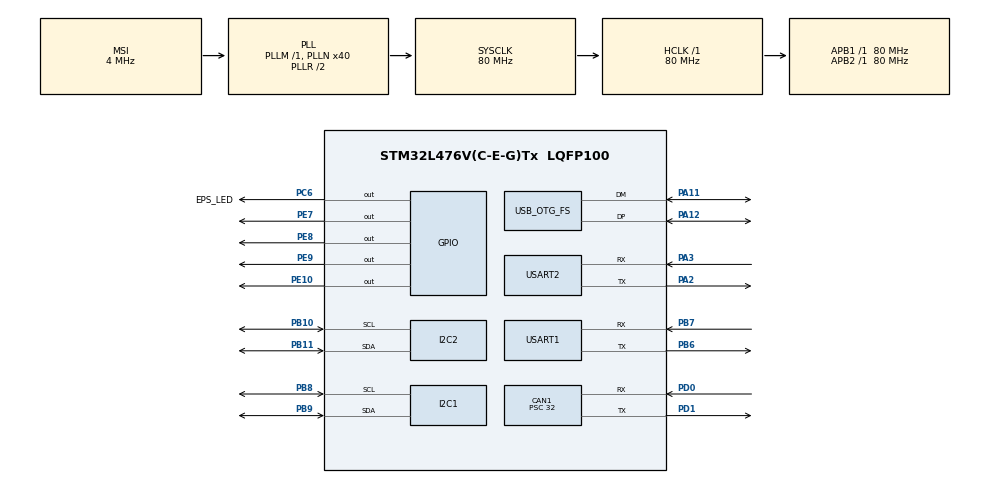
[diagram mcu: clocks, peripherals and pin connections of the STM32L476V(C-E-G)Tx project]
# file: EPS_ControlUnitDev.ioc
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CAN1.CalculateBaudRate=833333
CAN1.CalculateTimeBit=1200
CAN1.CalculateTimeQuantum=400.0
CAN1.Prescaler=32
I2C1.Timing=0x10D19CE4
I2C2.Timing=0x10D19CE4
Mcu.Family=STM32L4
Mcu.Name=STM32L476V(C-E-G)Tx
Mcu.Package=LQFP100
NVIC.OTG_FS_IRQn=true\:0\:0\:false\:false\:true\:false\:true\:true
NVIC.PriorityGroup=NVIC_PRIORITYGROUP_4
PA11.Mode=Device_Only
PA11.Signal=USB_OTG_FS_DM
PA12.Mode=Device_Only
PA12.Signal=USB_OTG_FS_DP
PA13\ (JTMS-SWDIO).Mode=Serial_Wire
PA13\ (JTMS-SWDIO).Signal=SYS_JTMS-SWDIO
PA14\ (JTCK-SWCLK).Mode=Serial_Wire
PA14\ (JTCK-SWCLK).Signal=SYS_JTCK-SWCLK
PA2.Mode=Asynchronous
PA2.Signal=USART2_TX
PA3.Mode=Asynchronous
PA3.Signal=USART2_RX
PB10.Mode=I2C
PB10.Signal=I2C2_SCL
PB11.Mode=I2C
PB11.Signal=I2C2_SDA
PB6.Mode=Asynchronous
PB6.Signal=USART1_TX
PB7.Mode=Asynchronous
PB7.Signal=USART1_RX
PB8.Mode=I2C
PB8.Signal=I2C1_SCL
PB9.Mode=I2C
PB9.Signal=I2C1_SDA
PC6.GPIO_Label=EPS_LED
PC6.Signal=GPIO_Output
PD0.Mode=CAN_Activate
PD0.Signal=CAN1_RX
PD1.Mode=CAN_Activate
PD1.Signal=CAN1_TX
PE10.Signal=GPIO_Output
PE7.Signal=GPIO_Output
PE8.Signal=GPIO_Output
PE9.Signal=GPIO_Output
PH0-OSC_IN\ (PH0).Mode=HSE-External-Oscillator
PH0-OSC_IN\ (PH0).Signal=RCC_OSC_IN
PH1-OSC_OUT\ (PH1).Mode=HSE-External-Oscillator
PH1-OSC_OUT\ (PH1).Signal=RCC_OSC_OUT
ProjectManager.HeapSize=0x200
ProjectManager.StackSize=0x400
ProjectManager.TargetToolchain=STM32CubeIDE
RCC.ADCFreq_Value=48000000
RCC.AHBFreq_Value=80000000
RCC.APB1Freq_Value=80000000
RCC.APB1TimFreq_Value=80000000
RCC.APB2Freq_Value=80000000
RCC.APB2TimFreq_Value=80000000
RCC.CortexFreq_Value=80000000
RCC.HCLKFreq_Value=80000000
RCC.HSE_VALUE=32000000
RCC.HSI_VALUE=16000000
RCC.LSE_VALUE=32768
RCC.MSI_VALUE=4000000
RCC.PLLN=40
RCC.PLLSAI1N=24
RCC.SYSCLKFreq_VALUE=80000000
RCC.SYSCLKSource=RCC_SYSCLKSOURCE_PLLCLK
RCC.USBFreq_Value=48000000
RCC.VCOOutputFreq_Value=160000000
USART1.VirtualMode-Asynchronous=VM_ASYNC
USART2.VirtualMode-Asynchronous=VM_ASYNC
USB_DEVICE.CLASS_NAME_FS=CDC
USB_DEVICE.VirtualMode=Cdc
USB_DEVICE.VirtualModeFS=Cdc_FS
USB_OTG_FS.VirtualMode=Device_Only
VP_USB_DEVICE_VS_USB_DEVICE_CDC_FS.Mode=CDC_FS
board=custom

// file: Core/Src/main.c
/* USER CODE BEGIN Header */
/**
  ******************************************************************************
  * @file           : main.c
  * @brief          : Main program body
  ******************************************************************************
  * @attention
  *
  * Copyright (c) 2024 STMicroelectronics.
  * All rights reserved.
  *
  * This software is licensed under terms that can be found in the LICENSE file
  * in the root directory of this software component.
  * If no LICENSE file comes with this software, it is provided AS-IS.
  *
  ******************************************************************************
  */
/* USER CODE END Header */
#include "main.h"
#include "usb_device.h"

CAN_HandleTypeDef hcan1;

I2C_HandleTypeDef hi2c1;
I2C_HandleTypeDef hi2c2;

UART_HandleTypeDef huart1;
UART_HandleTypeDef huart2;

/* USER CODE BEGIN PV */
int blinktime = 100;
/* USER CODE END PV */

void SystemClock_Config(void);
static void MX_GPIO_Init(void);
static void MX_CAN1_Init(void);
static void MX_I2C1_Init(void);
static void MX_I2C2_Init(void);
static void MX_USART1_UART_Init(void);
static void MX_USART2_UART_Init(void);

int main(void)
{

  /* MCU Configuration--------------------------------------------------------*/

  /* Reset of all peripherals, Initializes the Flash interface and the Systick. */
  HAL_Init();

  /* Configure the system clock */
  SystemClock_Config();

  /* Initialize all configured peripherals */
  MX_GPIO_Init();
  MX_CAN1_Init();
  MX_I2C1_Init();
  MX_I2C2_Init();
  MX_USART1_UART_Init();
  MX_USART2_UART_Init();
  MX_USB_DEVICE_Init();

  /* Infinite loop */
  while (1)
  {
	  HAL_GPIO_TogglePin (GPIOC, EPS_LED_Pin);
	  HAL_Delay (blinktime);   /* Insert delay 100 ms */
  }
}

void SystemClock_Config(void)
{
  RCC_OscInitTypeDef RCC_OscInitStruct = {0};
  RCC_ClkInitTypeDef RCC_ClkInitStruct = {0};

  /** Configure the main internal regulator output voltage
  */
  if (HAL_PWREx_ControlVoltageScaling(PWR_REGULATOR_VOLTAGE_SCALE1) != HAL_OK)
  {
    Error_Handler();
  }

  /** Initializes the RCC Oscillators according to the specified parameters
  * in the RCC_OscInitTypeDef structure.
  */
  RCC_OscInitStruct.OscillatorType = RCC_OSCILLATORTYPE_MSI;
  RCC_OscInitStruct.MSIState = RCC_MSI_ON;
  RCC_OscInitStruct.MSICalibrationValue = 0;
  RCC_OscInitStruct.MSIClockRange = RCC_MSIRANGE_6;
  RCC_OscInitStruct.PLL.PLLState = RCC_PLL_ON;
  RCC_OscInitStruct.PLL.PLLSource = RCC_PLLSOURCE_MSI;
  RCC_OscInitStruct.PLL.PLLM = 1;
  RCC_OscInitStruct.PLL.PLLN = 40;
  RCC_OscInitStruct.PLL.PLLP = RCC_PLLP_DIV7;
  RCC_OscInitStruct.PLL.PLLQ = RCC_PLLQ_DIV2;
  RCC_OscInitStruct.PLL.PLLR = RCC_PLLR_DIV2;
  if (HAL_RCC_OscConfig(&RCC_OscInitStruct) != HAL_OK)
  {
    Error_Handler();
  }

  /** Initializes the CPU, AHB and APB buses clocks
  */
  RCC_ClkInitStruct.ClockType = RCC_CLOCKTYPE_HCLK|RCC_CLOCKTYPE_SYSCLK
                              |RCC_CLOCKTYPE_PCLK1|RCC_CLOCKTYPE_PCLK2;
  RCC_ClkInitStruct.SYSCLKSource = RCC_SYSCLKSOURCE_PLLCLK;
  RCC_ClkInitStruct.AHBCLKDivider = RCC_SYSCLK_DIV1;
  RCC_ClkInitStruct.APB1CLKDivider = RCC_HCLK_DIV1;
  RCC_ClkInitStruct.APB2CLKDivider = RCC_HCLK_DIV1;

  if (HAL_RCC_ClockConfig(&RCC_ClkInitStruct, FLASH_LATENCY_4) != HAL_OK)
  {
    Error_Handler();
  }
}

static void MX_CAN1_Init(void)
{

  hcan1.Instance = CAN1;
  hcan1.Init.Prescaler = 32;
  hcan1.Init.Mode = CAN_MODE_NORMAL;
  hcan1.Init.SyncJumpWidth = CAN_SJW_1TQ;
  hcan1.Init.TimeSeg1 = CAN_BS1_1TQ;
  hcan1.Init.TimeSeg2 = CAN_BS2_1TQ;
  hcan1.Init.TimeTriggeredMode = DISABLE;
  hcan1.Init.AutoBusOff = DISABLE;
  hcan1.Init.AutoWakeUp = DISABLE;
  hcan1.Init.AutoRetransmission = DISABLE;
  hcan1.Init.ReceiveFifoLocked = DISABLE;
  hcan1.Init.TransmitFifoPriority = DISABLE;
  if (HAL_CAN_Init(&hcan1) != HAL_OK)
  {
    Error_Handler();
  }

}

static void MX_I2C1_Init(void)
{

  hi2c1.Instance = I2C1;
  hi2c1.Init.Timing = 0x10D19CE4;
  hi2c1.Init.OwnAddress1 = 0;
  hi2c1.Init.AddressingMode = I2C_ADDRESSINGMODE_7BIT;
  hi2c1.Init.DualAddressMode = I2C_DUALADDRESS_DISABLE;
  hi2c1.Init.OwnAddress2 = 0;
  hi2c1.Init.OwnAddress2Masks = I2C_OA2_NOMASK;
  hi2c1.Init.GeneralCallMode = I2C_GENERALCALL_DISABLE;
  hi2c1.Init.NoStretchMode = I2C_NOSTRETCH_DISABLE;
  if (HAL_I2C_Init(&hi2c1) != HAL_OK)
  {
    Error_Handler();
  }

  /** Configure Analogue filter
  */
  if (HAL_I2CEx_ConfigAnalogFilter(&hi2c1, I2C_ANALOGFILTER_ENABLE) != HAL_OK)
  {
    Error_Handler();
  }

  /** Configure Digital filter
  */
  if (HAL_I2CEx_ConfigDigitalFilter(&hi2c1, 0) != HAL_OK)
  {
    Error_Handler();
  }

}

static void MX_I2C2_Init(void)
{

  hi2c2.Instance = I2C2;
  hi2c2.Init.Timing = 0x10D19CE4;
  hi2c2.Init.OwnAddress1 = 0;
  hi2c2.Init.AddressingMode = I2C_ADDRESSINGMODE_7BIT;
  hi2c2.Init.DualAddressMode = I2C_DUALADDRESS_DISABLE;
  hi2c2.Init.OwnAddress2 = 0;
  hi2c2.Init.OwnAddress2Masks = I2C_OA2_NOMASK;
  hi2c2.Init.GeneralCallMode = I2C_GENERALCALL_DISABLE;
  hi2c2.Init.NoStretchMode = I2C_NOSTRETCH_DISABLE;
  if (HAL_I2C_Init(&hi2c2) != HAL_OK)
  {
    Error_Handler();
  }

  /** Configure Analogue filter
  */
  if (HAL_I2CEx_ConfigAnalogFilter(&hi2c2, I2C_ANALOGFILTER_ENABLE) != HAL_OK)
  {
    Error_Handler();
  }

  /** Configure Digital filter
  */
  if (HAL_I2CEx_ConfigDigitalFilter(&hi2c2, 0) != HAL_OK)
  {
    Error_Handler();
  }

}

static void MX_USART1_UART_Init(void)
{

  huart1.Instance = USART1;
  huart1.Init.BaudRate = 115200;
  huart1.Init.WordLength = UART_WORDLENGTH_8B;
  huart1.Init.StopBits = UART_STOPBITS_1;
  huart1.Init.Parity = UART_PARITY_NONE;
  huart1.Init.Mode = UART_MODE_TX_RX;
  huart1.Init.HwFlowCtl = UART_HWCONTROL_NONE;
  huart1.Init.OverSampling = UART_OVERSAMPLING_16;
  huart1.Init.OneBitSampling = UART_ONE_BIT_SAMPLE_DISABLE;
  huart1.AdvancedInit.AdvFeatureInit = UART_ADVFEATURE_NO_INIT;
  if (HAL_UART_Init(&huart1) != HAL_OK)
  {
    Error_Handler();
  }

}

static void MX_USART2_UART_Init(void)
{

  huart2.Instance = USART2;
  huart2.Init.BaudRate = 115200;
  huart2.Init.WordLength = UART_WORDLENGTH_8B;
  huart2.Init.StopBits = UART_STOPBITS_1;
  huart2.Init.Parity = UART_PARITY_NONE;
  huart2.Init.Mode = UART_MODE_TX_RX;
  huart2.Init.HwFlowCtl = UART_HWCONTROL_NONE;
  huart2.Init.OverSampling = UART_OVERSAMPLING_16;
  huart2.Init.OneBitSampling = UART_ONE_BIT_SAMPLE_DISABLE;
  huart2.AdvancedInit.AdvFeatureInit = UART_ADVFEATURE_NO_INIT;
  if (HAL_UART_Init(&huart2) != HAL_OK)
  {
    Error_Handler();
  }

}

static void MX_GPIO_Init(void)
{
  GPIO_InitTypeDef GPIO_InitStruct = {0};

  /* GPIO Ports Clock Enable */
  __HAL_RCC_GPIOH_CLK_ENABLE();
  __HAL_RCC_GPIOA_CLK_ENABLE();
  __HAL_RCC_GPIOE_CLK_ENABLE();
  __HAL_RCC_GPIOB_CLK_ENABLE();
  __HAL_RCC_GPIOC_CLK_ENABLE();
  __HAL_RCC_GPIOD_CLK_ENABLE();

  /*Configure GPIO pin Output Level */
  HAL_GPIO_WritePin(GPIOE, GPIO_PIN_7|GPIO_PIN_8|GPIO_PIN_9|GPIO_PIN_10, GPIO_PIN_RESET);

  /*Configure GPIO pin Output Level */
  HAL_GPIO_WritePin(EPS_LED_GPIO_Port, EPS_LED_Pin, GPIO_PIN_RESET);

  /*Configure GPIO pins : PE7 PE8 PE9 PE10 */
  GPIO_InitStruct.Pin = GPIO_PIN_7|GPIO_PIN_8|GPIO_PIN_9|GPIO_PIN_10;
  GPIO_InitStruct.Mode = GPIO_MODE_OUTPUT_PP;
  GPIO_InitStruct.Pull = GPIO_NOPULL;
  GPIO_InitStruct.Speed = GPIO_SPEED_FREQ_LOW;
  HAL_GPIO_Init(GPIOE, &GPIO_InitStruct);

  /*Configure GPIO pin : EPS_LED_Pin */
  GPIO_InitStruct.Pin = EPS_LED_Pin;
  GPIO_InitStruct.Mode = GPIO_MODE_OUTPUT_PP;
  GPIO_InitStruct.Pull = GPIO_NOPULL;
  GPIO_InitStruct.Speed = GPIO_SPEED_FREQ_LOW;
  HAL_GPIO_Init(EPS_LED_GPIO_Port, &GPIO_InitStruct);

}

void Error_Handler(void)
{
  __disable_irq();
  while (1)
  {
  }
}
